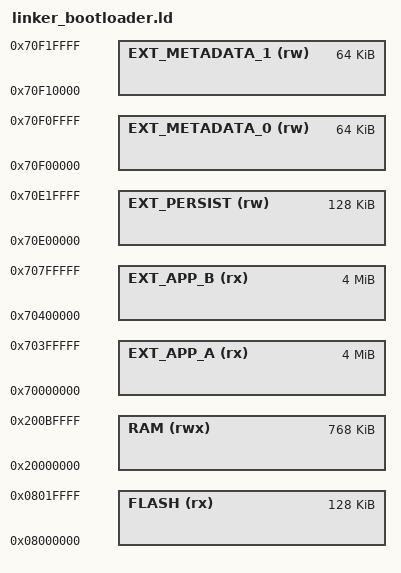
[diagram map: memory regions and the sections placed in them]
/* STM32U7 external-flash template. Configure XSPI/OSPI and TrustZone policy during porting. */
MEMORY
{
  FLASH (rx) : ORIGIN = 0x08000000, LENGTH = 128K
  EXT_APP_A (rx) : ORIGIN = 0x70000000, LENGTH = 4096K
  EXT_APP_B (rx) : ORIGIN = 0x70400000, LENGTH = 4096K
  EXT_PERSIST (rw) : ORIGIN = 0x70E00000, LENGTH = 128K
  EXT_METADATA_0 (rw) : ORIGIN = 0x70F00000, LENGTH = 64K
  EXT_METADATA_1 (rw) : ORIGIN = 0x70F10000, LENGTH = 64K
  RAM (rwx)  : ORIGIN = 0x20000000, LENGTH = 768K
}
